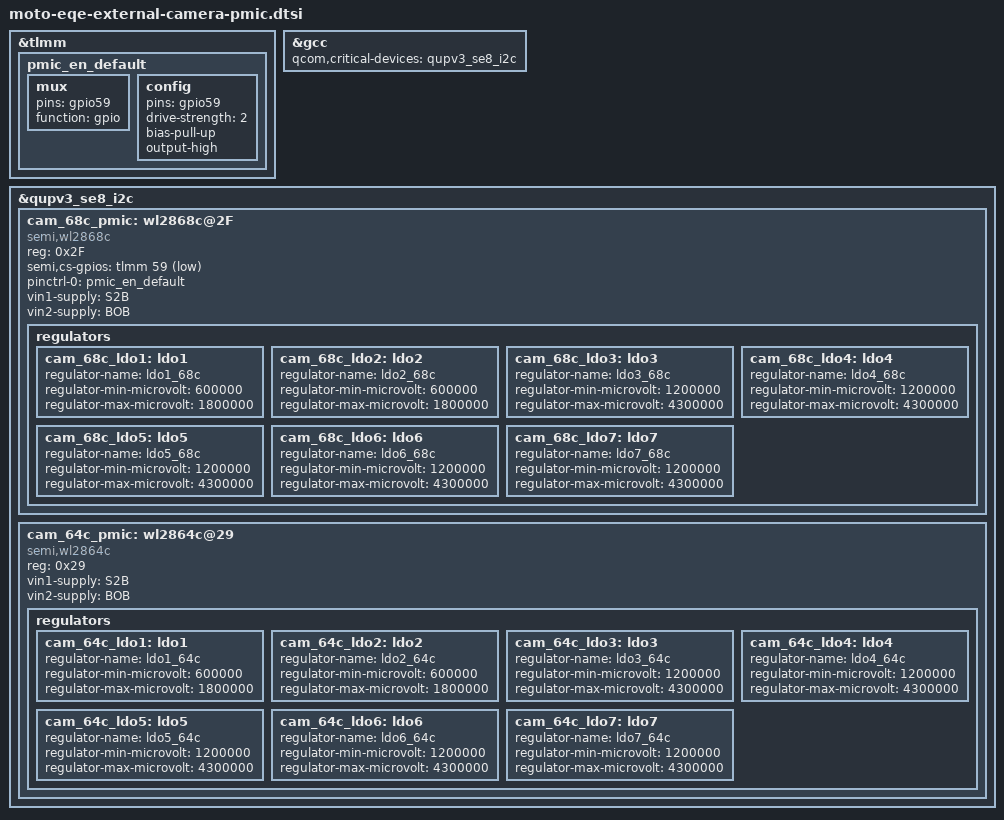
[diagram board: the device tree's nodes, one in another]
&tlmm{
    pmic_en_default: pmic_en_default {
        mux {
            pins = "gpio59";
            function = "gpio";
        };
        config {
            pins = "gpio59";
            drive-strength = <2>;
            bias-pull-up;
            output-high;
        };
    };
};

/*
 * Each QUP device that's a parent to PMIC must be listed as a critical device
 * to GCC.
 */
&gcc {
    qcom,critical-devices = <&qupv3_se8_i2c>;
};

&qupv3_se8_i2c {
    status = "ok";

    cam_68c_pmic: wl2868c@2F{
        compatible = "semi,wl2868c";
        reg = <0x2F>;
        semi,cs-gpios = <&tlmm 59 1>;
        pinctrl-names = "default";
        pinctrl-0 = <&pmic_en_default>;
        vin1-supply = <&S2B>;
        vin2-supply = <&BOB>;

        regulators {
            cam_68c_ldo1: ldo1 {
                regulator-name = "ldo1_68c";
                regulator-min-microvolt = <600000>;
                regulator-max-microvolt = <1800000>;
            };

            cam_68c_ldo2: ldo2 {
                regulator-name = "ldo2_68c";
                regulator-min-microvolt = <600000>;
                regulator-max-microvolt = <1800000>;
            };

            cam_68c_ldo3: ldo3 {
                regulator-name = "ldo3_68c";
                regulator-min-microvolt = <1200000>;
                regulator-max-microvolt = <4300000>;
            };

            cam_68c_ldo4: ldo4 {
                regulator-name = "ldo4_68c";
                regulator-min-microvolt = <1200000>;
                regulator-max-microvolt = <4300000>;
            };

            cam_68c_ldo5: ldo5 {
                regulator-name = "ldo5_68c";
                regulator-min-microvolt = <1200000>;
                regulator-max-microvolt = <4300000>;
            };

            cam_68c_ldo6: ldo6 {
                regulator-name = "ldo6_68c";
                regulator-min-microvolt = <1200000>;
                regulator-max-microvolt = <4300000>;
            };

            cam_68c_ldo7: ldo7 {
                regulator-name = "ldo7_68c";
                regulator-min-microvolt = <1200000>;
                regulator-max-microvolt = <4300000>;
            };
        };
    };

    cam_64c_pmic: wl2864c@29{
        compatible = "semi,wl2864c";
        reg = <0x29>;
        vin1-supply = <&S2B>;
        vin2-supply = <&BOB>;

        regulators {
            cam_64c_ldo1: ldo1 {
                regulator-name = "ldo1_64c";
                regulator-min-microvolt = <600000>;
                regulator-max-microvolt = <1800000>;
            };

            cam_64c_ldo2: ldo2 {
                regulator-name = "ldo2_64c";
                regulator-min-microvolt = <600000>;
                regulator-max-microvolt = <1800000>;
            };

            cam_64c_ldo3: ldo3 {
                regulator-name = "ldo3_64c";
                regulator-min-microvolt = <1200000>;
                regulator-max-microvolt = <4300000>;
            };

            cam_64c_ldo4: ldo4 {
                regulator-name = "ldo4_64c";
                regulator-min-microvolt = <1200000>;
                regulator-max-microvolt = <4300000>;
            };

            cam_64c_ldo5: ldo5 {
                regulator-name = "ldo5_64c";
                regulator-min-microvolt = <1200000>;
                regulator-max-microvolt = <4300000>;
            };

            cam_64c_ldo6: ldo6 {
                regulator-name = "ldo6_64c";
                regulator-min-microvolt = <1200000>;
                regulator-max-microvolt = <4300000>;
            };

            cam_64c_ldo7: ldo7 {
                regulator-name = "ldo7_64c";
                regulator-min-microvolt = <1200000>;
                regulator-max-microvolt = <4300000>;
            };
        };
    };
};
